# CY8C3246PVI_147 register map
File version: 0.1
CY8C32
Registers are 8-bit, read-write, no defined reset value unless marked. A register's access mark holds for its fields unless they carry their own. Offsets are from the block's base; lines under a group give offsets from that group; [hi:lo] are bit positions; {n}, {i} and the like mark numbered series; 'fields as' and 'values as' point back to an identical list; <NAME> marks a mode.

## Memory map
0x00000000 UART_RS485 — UART
0x00000000 MY_TIMER
0x00000000 PACER_TIMER
0x00000000 ADC
0x00000000 WATCHDOG_COUNTER
0x00000000 PWM_MOTORS
0x00000000 COUNTER_ENC
0x00006463 ADC_STATUS
0x00006467 FF_STATUS
0x00006470 ADC_SOC
0x00006473 MOTOR_ON_OFF
0x00006474 RESET_FF
0x00006475 FTDI_ENABLE_REG
0x00006476 RS485_CTS
0x0000647B WATCHDOG_ENABLER
0x0000647C WATCHDOG_REFRESH
0x00006577 RESET_COUNTERS
0x0000657A MOTOR_DIR
0x0000657B POWER_ON_LED_REG

## RS485_CTS
Base 0x00006476
0x00 RS485_CTS_CONTROL_REG

## FTDI_ENABLE_REG
Base 0x00006475
Registers as RS485_CTS (with RS485_CTS read as FTDI_ENABLE_REG).

## MOTOR_ON_OFF
Base 0x00006473
Registers as RS485_CTS (with RS485_CTS read as MOTOR_ON_OFF).

## POWER_ON_LED_REG
Base 0x0000657B
Registers as RS485_CTS (with RS485_CTS read as POWER_ON_LED_REG).

## ADC_SOC
Base 0x00006470
Registers as RS485_CTS (with RS485_CTS read as ADC_SOC).

## MOTOR_DIR
Base 0x0000657A
Registers as RS485_CTS (with RS485_CTS read as MOTOR_DIR).

## RESET_COUNTERS
Base 0x00006577
Registers as RS485_CTS (with RS485_CTS read as RESET_COUNTERS).

## WATCHDOG_ENABLER
Base 0x0000647B
Registers as RS485_CTS (with RS485_CTS read as WATCHDOG_ENABLER).

## WATCHDOG_REFRESH
Base 0x0000647C
Registers as RS485_CTS (with RS485_CTS read as WATCHDOG_REFRESH).

## RESET_FF
Base 0x00006474
Registers as RS485_CTS (with RS485_CTS read as RESET_FF).

## UART_RS485 — UART
Base 0x00000000
0x644D TX_UART_RS485_TX_DATA — TX Data Register
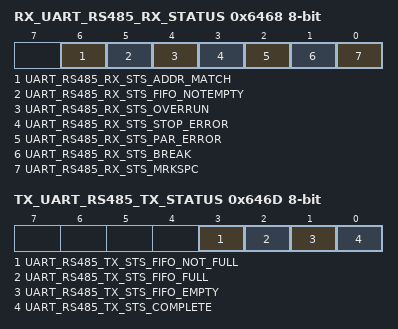
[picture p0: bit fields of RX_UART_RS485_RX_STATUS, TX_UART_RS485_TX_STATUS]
0x6468 RX_UART_RS485_RX_STATUS — RX status register
  [6] UART_RS485_RX_STS_ADDR_MATCH ro, [5] UART_RS485_RX_STS_FIFO_NOTEMPTY ro, [4] UART_RS485_RX_STS_OVERRUN ro, [3] UART_RS485_RX_STS_STOP_ERROR ro, [2] UART_RS485_RX_STS_PAR_ERROR ro, [1] UART_RS485_RX_STS_BREAK ro, [0] UART_RS485_RX_STS_MRKSPC ro
0x646D TX_UART_RS485_TX_STATUS — TX status register
  [3] UART_RS485_TX_STS_FIFO_NOT_FULL ro, [2] UART_RS485_TX_STS_FIFO_FULL ro, [1] UART_RS485_TX_STS_FIFO_EMPTY ro, [0] UART_RS485_TX_STS_COMPLETE ro
0x6528 RX_UART_RS485_RX_ADDRESS1 — RX Address1 Register
0x6538 RX_UART_RS485_RX_ADDRESS2 — RX Address2 Register
0x6548 RX_UART_RS485_RX_DATA — RX Data Register

## MY_TIMER
Base 0x00000000
0x6408 MY_TIMER_COUNTER 24-bit — UDB.A0 - Current Down Counter Value
0x6428 MY_TIMER_PERIOD 24-bit — UDB.D0 - Assigned Period
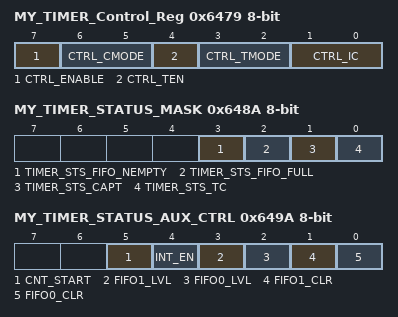
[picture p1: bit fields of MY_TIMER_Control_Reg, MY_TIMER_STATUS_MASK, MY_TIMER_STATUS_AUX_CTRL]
0x6479 MY_TIMER_Control_Reg — UDB Control Register - Assigned Control Register Value
  [7] CTRL_ENABLE — Enable the Timer
  [6:5] CTRL_CMODE — Capture Mode
  [4] CTRL_TEN — Trigger Enable Bit
  [3:2] CTRL_TMODE — Trigger Mode
  [1:0] CTRL_IC — Interrupt Count
0x648A MY_TIMER_STATUS_MASK — UDB Status bits Interrupt Mask Enable Register
  [3] TIMER_STS_FIFO_NEMPTY ro — FIFO Empty status
  [2] TIMER_STS_FIFO_FULL ro — FIFO Full Status
  [1] TIMER_STS_CAPT ro — Enables the Interrupt on Capture
  [0] TIMER_STS_TC ro — Enables the Interrupt on TC
0x649A MY_TIMER_STATUS_AUX_CTRL — UDB Auxilliary Control Register
  [5] CNT_START — FIFO0 clear
    0=E_CNT_START0 (Disable counter); 1=E_CNT_START1 (Enable counter)
  [4] INT_EN
    0=E_INT_EN0 (Interrupt disabled); 1=E_INT_EN1 (Interrupt enabled)
  [3] FIFO1_LVL — FIFO level
    0=E_FIFO_LVL_0 (FIFO LVL: input mode: FIFO not full; output mode: FIFO not empty); 1=E_FIFO_LVL_1 (FIFO LVL: input mode: FIFO at least 1/2 empty; output mode: FIFO at least 1/2 full)
  [2] FIFO0_LVL — FIFO level
    values as FIFO1_LVL
  [1] FIFO1_CLR — FIFO1 clear
    0=E_FIFO_CLR_0 (Normal FIFO operation); 1=E_FIFO_CLR_1 (Clear FIFO state)
  [0] FIFO0_CLR — FIFO0 clear
    values as FIFO1_CLR
